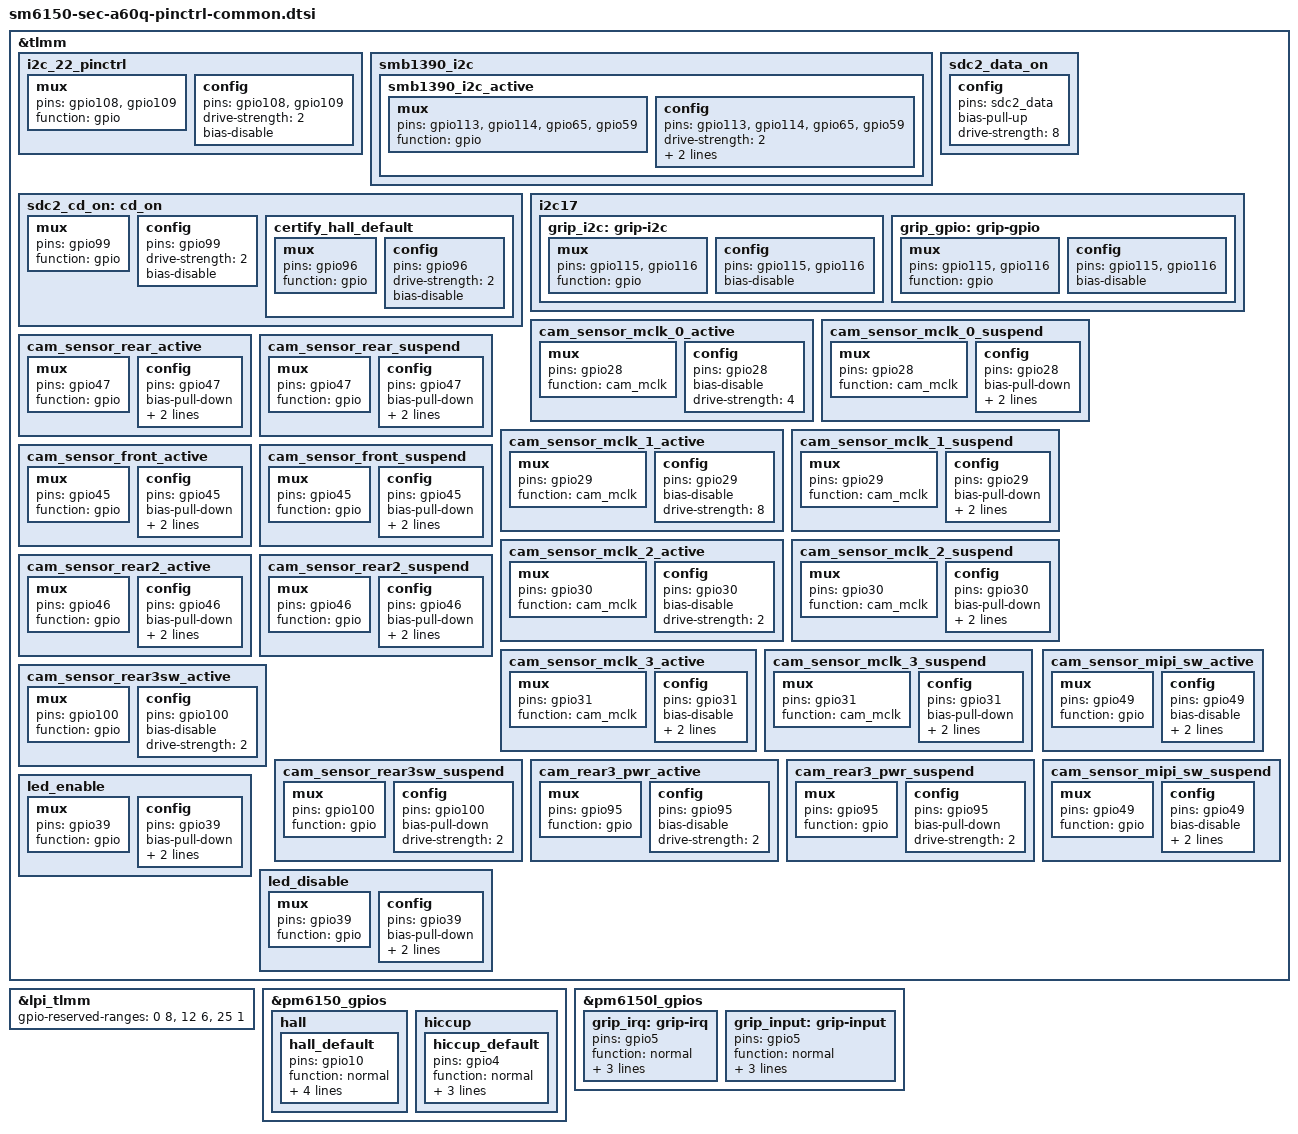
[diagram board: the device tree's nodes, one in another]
/* Copyright (c) 2018, The Linux Foundation. All rights reserved.
 *
 * This program is free software; you can redistribute it and/or modify
 * it under the terms of the GNU General Public License version 2 and
 * only version 2 as published by the Free Software Foundation.
 *
 * This program is distributed in the hope that it will be useful,
 * but WITHOUT ANY WARRANTY; without even the implied warranty of
 * MERCHANTABILITY or FITNESS FOR A PARTICULAR PURPOSE.  See the
 * GNU General Public License for more details.
 */

#include "sm6150-sec-a60q-audio-pinctrl.dtsi"

&tlmm {
	i2c_22_pinctrl: i2c_22_pinctrl {
		mux {
			pins = "gpio108",	/* DISP_PMIC_SDA_1P8 */
				   "gpio109";	/* DISP_PMIC_SCL_1P8 */
			function = "gpio";
		};
		config {
			pins = "gpio108",	/* DISP_PMIC_SDA_1P8 */
				   "gpio109";	/* DISP_PMIC_SCL_1P8 */
			drive-strength = <2>;
			bias-disable;
		};
	};
	/* smb1390 i2c */
	smb1390_i2c: smb1390_i2c {
		smb1390_i2c_active: smb1390_i2c_active {
			mux {
				pins = "gpio113", "gpio114","gpio65","gpio59";
				function = "gpio";
			};

			config {
				pins = "gpio113", "gpio114","gpio65","gpio59";
				drive-strength = <2>;
				bias-pull-down;	
				input-enable;				
			};
		};
	};


	sdc2_cd_on: cd_on {
		mux {
			pins = "gpio99";
			function = "gpio";
		};
		config {
			pins = "gpio99";
			drive-strength = <2>;
			bias-disable;
		};
		certify_hall_default: certify_hall_default {
			mux {
				pins = "gpio96";
				function = "gpio";
			};
			config {
				pins = "gpio96";
				drive-strength = <2>;
				bias-disable;
			};
		};
	};

	sdc2_data_on: sdc2_data_on {
		config {
			pins = "sdc2_data";
			bias-pull-up;		/* pull up */
			drive-strength = <8>;	/* 8 MA */
		};
	};

	i2c17 {
		grip_i2c: grip-i2c {
			mux {
				pins = "gpio115",	/* GRIP_SENSOR_SDA_1P8 */
				   	"gpio116";	/* GRIP_SENSOR_SCL_1P8 */
				function = "gpio";
			};
			config {
				pins = "gpio115",	/* GRIP_SENSOR_SDA_1P8 */
				   	"gpio116";	/* GRIP_SENSOR_SCL_1P8 */
				bias-disable;
			};
		};

		grip_gpio: grip-gpio {
			mux {
				pins = "gpio115",	/* GRIP_SENSOR_SDA_1P8 */
				   	"gpio116";	/* GRIP_SENSOR_SCL_1P8 */
				function = "gpio";
			};
			config {
				pins = "gpio115",	/* GRIP_SENSOR_SDA_1P8 */
				   	"gpio116";	/* GRIP_SENSOR_SCL_1P8 */
				bias-disable;
			};
		};
	};

       cam_sensor_mclk_0_active: cam_sensor_mclk_0_active {
	/* REAR MCLK */
		mux {
			pins = "gpio28";
			function = "cam_mclk";
		};
		config {
			pins = "gpio28";
			bias-disable; /* No PULL */
			drive-strength = <4>; /* 4 MA */
		};
	};

       cam_sensor_mclk_0_suspend: cam_sensor_mclk_0_suspend {
	/* REAR MCLK */
		mux {
			pins = "gpio28";
			function = "cam_mclk";
		};
		config {
			pins = "gpio28";
			bias-pull-down; /* PULL DOWN */
			drive-strength = <4>; /* 4 MA */
			output-low;
		};
	};

	cam_sensor_rear_active: cam_sensor_rear_active {
	/* REAR RESET */
		mux {
			pins = "gpio47";
			function = "gpio";
		};
		config {
			pins = "gpio47";
			bias-pull-down; /* PULL DOWN */
			drive-strength = <2>; /* 2 MA */
			output-low;
		};
	};

	cam_sensor_rear_suspend: cam_sensor_rear_suspend {
	/* REAR RESET */
		mux {
			pins = "gpio47";
			function = "gpio";
		};
		config {
			pins = "gpio47";
			bias-pull-down; /* PULL DOWN */
			drive-strength = <2>; /* 2 MA */
			output-low;
		};
	};

	cam_sensor_mclk_1_active: cam_sensor_mclk_1_active {
	/* FRONT MCLK */
		mux {
			pins = "gpio29";
			function = "cam_mclk";
		};
		config {
			pins = "gpio29";
			bias-disable; /* No PULL */
			drive-strength = <8>; /* 8 MA */
		};
	};

    	cam_sensor_mclk_1_suspend: cam_sensor_mclk_1_suspend {
	/* FRONT MCLK */
		mux {
			pins = "gpio29";
			function = "cam_mclk";
		};
		config {
			pins = "gpio29";
			bias-pull-down; /* PULL DOWN */
			drive-strength = <8>; /* 8 MA */
			output-low;
		};
	};
	cam_sensor_front_active: cam_sensor_front_active {
	/* FRONT RESET */
		mux {
			pins = "gpio45";
			function = "gpio";
		};
		config {
			pins = "gpio45";
			bias-pull-down; /* PULL DOWN */
			drive-strength = <2>; /* 2 MA */
			output-low;
		};
	};

	cam_sensor_front_suspend: cam_sensor_front_suspend {
	/* FRONT RESET */
		mux {
			pins = "gpio45";
			function = "gpio";
		};
		config {
			pins = "gpio45";
			bias-pull-down; /* PULL DOWN */
			drive-strength = <2>; /* 2 MA */
			output-low;
		};
	};
	
    	cam_sensor_mclk_2_active: cam_sensor_mclk_2_active {
	/* REAR2 MCLK */
		mux {
			pins = "gpio30";
			function = "cam_mclk";
		};
		config {
			pins = "gpio30";
			bias-disable; /* No PULL */
			drive-strength = <2>; /* 2 MA */
		};
	};

       cam_sensor_mclk_2_suspend: cam_sensor_mclk_2_suspend {
	/* REAR2 MCLK */
		mux {
			pins = "gpio30";
			function = "cam_mclk";
		};
		config {
			pins = "gpio30";
			bias-pull-down; /* PULL DOWN */
			drive-strength = <2>; /* 2 MA */
			output-low;
		};
	};
	cam_sensor_rear2_active: cam_sensor_rear2_active {
	/* REAR2 RESET */
		mux {
			pins = "gpio46";
			function = "gpio";
		};
		config {
			pins = "gpio46";
			bias-pull-down; /* PULL DOWN */
			drive-strength = <2>; /* 2 MA */
			output-low;
		};
	};

	cam_sensor_rear2_suspend: cam_sensor_rear2_suspend {
	/* REAR2 RESET */
		mux {
			pins = "gpio46";
			function = "gpio";
		};
		config {
			pins = "gpio46";
			bias-pull-down; /* PULL DOWN */
			drive-strength = <2>; /* 2 MA */
			output-low;
		};
	};
    	cam_sensor_mclk_3_active: cam_sensor_mclk_3_active {
	/* REAR SW-8M */
		mux {
				pins = "gpio31";
				function = "cam_mclk";
		};
		config {
				pins = "gpio31";
				bias-disable; /* No PULL */
				drive-strength = <4>; /* 2 MA */
				output-low;
		};
	};

	cam_sensor_mclk_3_suspend: cam_sensor_mclk_3_suspend {
	/* REAR SW-8M */
		mux {
				pins = "gpio31";
				function = "cam_mclk";
		};
		config {
				pins = "gpio31";
				bias-pull-down; /* PULL DOWN */
				drive-strength = <4>; /* 2 MA */
				output-low;
		};
	};


	cam_sensor_rear3sw_active: cam_sensor_rear3sw_active {
	/* REAR SUB2 RESET*/
		mux {
				pins = "gpio100";
				function = "gpio";
		};
		config {
				pins = "gpio100";
				bias-disable; /* No PULL */
				drive-strength = <2>; /* 2 MA */
		};
	};

	cam_sensor_rear3sw_suspend: cam_sensor_rear3sw_suspend {
	/* REAR SUB2 RESET */
		mux {
				pins = "gpio100";
				function = "gpio";
		};
		config {
				pins = "gpio100";
				bias-pull-down; /* PULL DOWN */
				drive-strength = <2>; /* 2 MA */
		};
	};

	cam_rear3_pwr_active: cam_rear3_pwr_active {
	/* REAR SUB2 RESET*/
		mux {
				pins = "gpio95";
				function = "gpio";
		};
		config {
				pins = "gpio95";
				bias-disable; /* No PULL */
				drive-strength = <2>; /* 2 MA */
		};
	};

	cam_rear3_pwr_suspend: cam_rear3_pwr_suspend {
	/* REAR SUB2 RESET */
		mux {
				pins = "gpio95";
				function = "gpio";
		};
		config {
				pins = "gpio95";
				bias-pull-down; /* PULL DOWN */
				drive-strength = <2>; /* 2 MA */
		};
	};
		cam_sensor_mipi_sw_active: cam_sensor_mipi_sw_active {
        /* MIPI_SWITCH */
                mux {
                        pins = "gpio49";
                        function = "gpio";
                };
                config {
                        pins = "gpio49";
                        bias-disable; /* No PULL */
                        output-high;
                        drive-strength = <2>; /* 2 MA */
                };
        };

        cam_sensor_mipi_sw_suspend: cam_sensor_mipi_sw_suspend {
        /* MIPI_SWITCH */
                mux {
                        pins = "gpio49";
                        function = "gpio";
                };
                config {
                        pins = "gpio49";
                        bias-disable; /* No PULL */
                        output-high;
                        drive-strength = <2>; /* 2 MA */
                };
        };

        led_enable: led_enable {
                mux {
                        pins = "gpio39";
                        function = "gpio";
                };

                config {
                        pins = "gpio39";
                        bias-pull-down; /* PULL DOWN */
                        drive-strength = <2>; /* 2 MA */
                        output-low;
                };
        };

        led_disable: led_disable {
                mux {
                        pins = "gpio39";
                        function = "gpio";
                };

                config {
                        pins = "gpio39";
                        bias-pull-down; /* PULL DOWN */
                        drive-strength = <2>; /* 2 MA */
                        output-low;
                };
        };        
};

&lpi_tlmm {
	gpio-reserved-ranges = <0 8>, <12 6>, <25 1>;
};

&pm6150_gpios {
	hall {
		hall_default: hall_default {
			pins = "gpio10";
			function = "normal";
			output-disable;
			input-enable;
			bias-disable;
			power-source = <0>;
		};
	};

	hiccup {
		hiccup_default: hiccup_default {
			pins = "gpio4";
			function = "normal";
			output-low;
			bias-disable;
			power-source = <0>;
		};
	};
};

&pm6150l_gpios {
	grip_irq: grip-irq {
		pins = "gpio5";
		function = "normal";
		power-source = <0>;
		input-enable;
		bias-disable;
	};
	grip_input: grip-input {
		pins = "gpio5";
		function = "normal";
		power-source = <0>;
		input-enable;
		bias-disable;
	};
};



